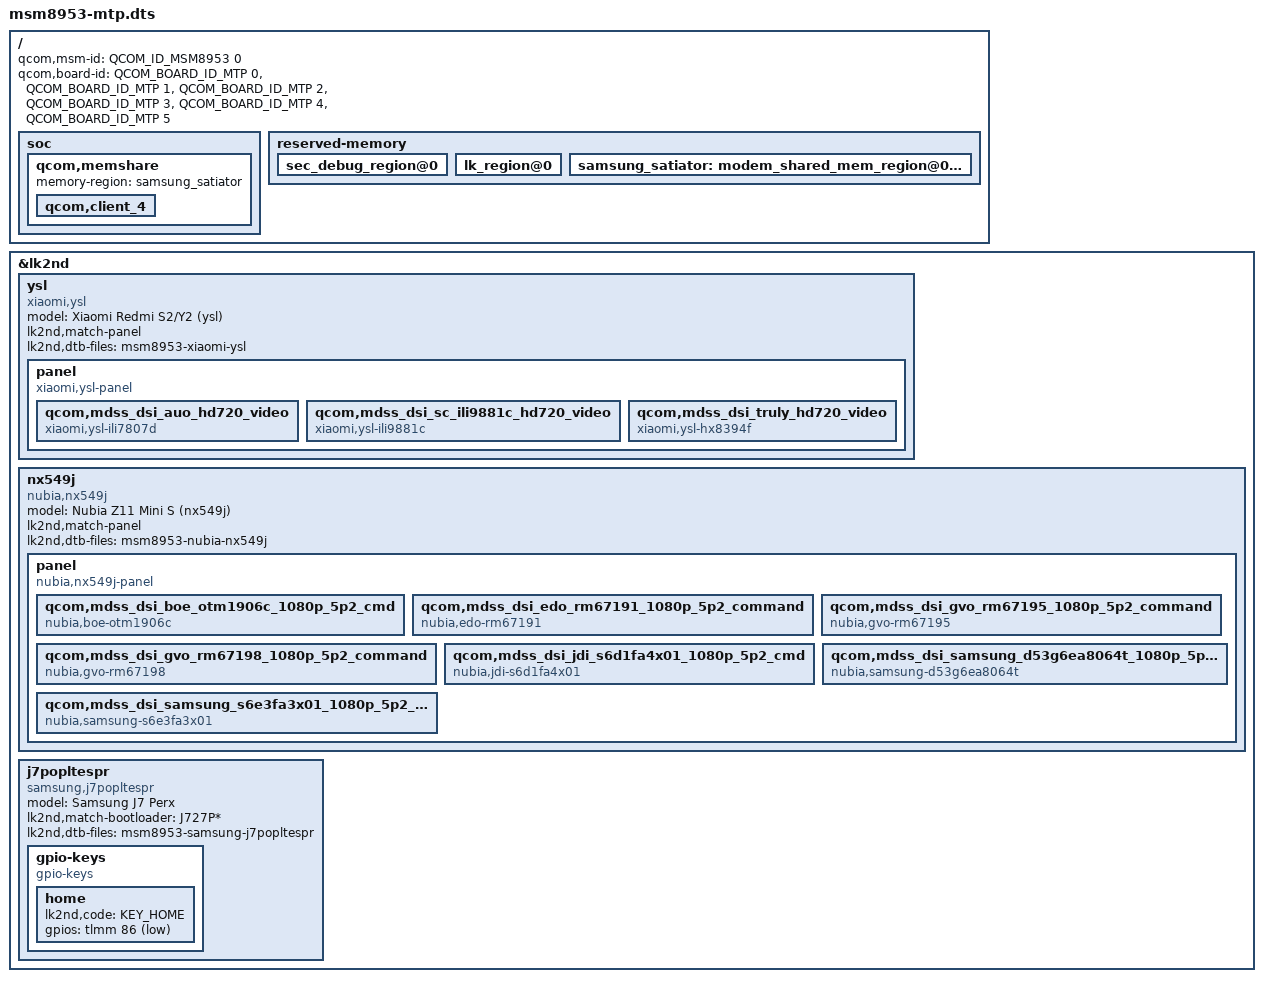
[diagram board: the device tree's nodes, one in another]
// SPDX-License-Identifier: GPL-2.0-only

/dts-v1/;

#include <skeleton64.dtsi>
#include <lk2nd.dtsi>

/ {
	qcom,msm-id = <QCOM_ID_MSM8953 0>;
	qcom,board-id = <QCOM_BOARD_ID_MTP 0>,
			<QCOM_BOARD_ID_MTP 1>,
			<QCOM_BOARD_ID_MTP 2>,
			<QCOM_BOARD_ID_MTP 3>,
			<QCOM_BOARD_ID_MTP 4>,
			<QCOM_BOARD_ID_MTP 5>;

	/* required for j7poplte bootloader */ 
	soc {
		qcom,memshare {
			memory-region = <&samsung_satiator>;
			qcom,client_4 {};
		};
	};

	reserved-memory {
		#address-cells = <2>;
		#size-cells = <2>;
		ranges;
		
		sec_debug_region@0 {};

		lk_region@0 {};

		samsung_satiator: modem_shared_mem_region@0x93000000 {};
	};
};

&lk2nd {
	ysl {
		model = "Xiaomi Redmi S2/Y2 (ysl)";
		compatible = "xiaomi,ysl";
		lk2nd,match-panel;

		lk2nd,dtb-files = "msm8953-xiaomi-ysl";

		panel {
			compatible = "xiaomi,ysl-panel", "lk2nd,panel";

			qcom,mdss_dsi_auo_hd720_video {
				compatible = "xiaomi,ysl-ili7807d";
			};
			qcom,mdss_dsi_sc_ili9881c_hd720_video {
				compatible = "xiaomi,ysl-ili9881c";
			};
			qcom,mdss_dsi_truly_hd720_video {
				compatible = "xiaomi,ysl-hx8394f";
			};
		};
	};

	nx549j {
		/*
		 * This device has a quirk you need to keep in mind when building
		 * and flashing lk2nd:
		 *
		 *    The stock bootloader does not like images built with embedded QCDT.
		 *    Therefor LK2ND_QCDTBS="" must be set when building.
		 */
		model = "Nubia Z11 Mini S (nx549j)";
		compatible = "nubia,nx549j";
		lk2nd,match-panel;

		lk2nd,dtb-files = "msm8953-nubia-nx549j";

		panel {
			compatible = "nubia,nx549j-panel", "lk2nd,panel";

			qcom,mdss_dsi_boe_otm1906c_1080p_5p2_cmd {
				compatible = "nubia,boe-otm1906c";
			};
			qcom,mdss_dsi_edo_rm67191_1080p_5p2_command {
				compatible = "nubia,edo-rm67191";
			};
			qcom,mdss_dsi_gvo_rm67195_1080p_5p2_command {
				compatible = "nubia,gvo-rm67195";
			};
			qcom,mdss_dsi_gvo_rm67198_1080p_5p2_command {
				compatible = "nubia,gvo-rm67198";
			};
			qcom,mdss_dsi_jdi_s6d1fa4x01_1080p_5p2_cmd {
				compatible = "nubia,jdi-s6d1fa4x01";
			};
			qcom,mdss_dsi_samsung_d53g6ea8064t_1080p_5p2_command {
				compatible = "nubia,samsung-d53g6ea8064t";
			};
			qcom,mdss_dsi_samsung_s6e3fa3x01_1080p_5p2_command {
				compatible = "nubia,samsung-s6e3fa3x01";
			};
		};
	};

	j7popltespr {
		model = "Samsung J7 Perx";
		compatible = "samsung,j7popltespr";
		lk2nd,match-bootloader = "J727P*";
		
		lk2nd,dtb-files = "msm8953-samsung-j7popltespr";

		gpio-keys {
			compatible = "gpio-keys";
			home {
				lk2nd,code = <KEY_HOME>;
				gpios = <&tlmm 86 (GPIO_ACTIVE_LOW | GPIO_PULL_UP)>;
			};
		};
	};
};
